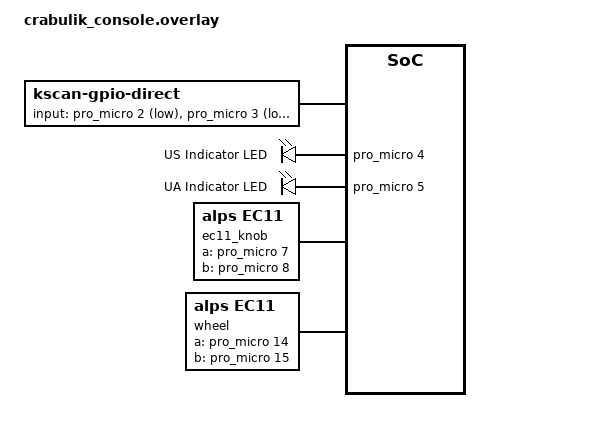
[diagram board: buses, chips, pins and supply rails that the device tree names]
#include <dt-bindings/zmk/matrix_transform.h>

/ {
    chosen {
        zmk,kscan = &kscan0;
    };

    /* Define the three physical switches wired to Ground */
    kscan0: kscan {
        compatible = "zmk,kscan-gpio-direct";
        label = "KSCAN";
        input-gpios
            = <&pro_micro 2 (GPIO_ACTIVE_LOW | GPIO_PULL_UP)> /* Button 1: US Layout */
            , <&pro_micro 3 (GPIO_ACTIVE_LOW | GPIO_PULL_UP)> /* Button 2: UA Layout */
            , <&pro_micro 6 (GPIO_ACTIVE_LOW | GPIO_PULL_UP)> /* Button 3: host-switch layer (hold) */
            , <&pro_micro 9 (GPIO_ACTIVE_LOW | GPIO_PULL_UP)> /* Button 4: EC11 push-click */
            , <&pro_micro 18 (GPIO_ACTIVE_LOW | GPIO_PULL_UP)> /* Button 5: Prev track (P1.15) */
            , <&pro_micro 19 (GPIO_ACTIVE_LOW | GPIO_PULL_UP)>; /* Button 6: Next track (P0.02) */
    };

    /* Expose the LEDs to the OS for custom state mapping */
    leds {
        compatible = "gpio-leds";
        led_us: led_us {
            gpios = <&pro_micro 4 GPIO_ACTIVE_HIGH>;
            label = "US Indicator LED";
        };
        led_ua: led_ua {
            gpios = <&pro_micro 5 GPIO_ACTIVE_HIGH>;
            label = "UA Indicator LED";
        };
    };

    /* Rotary inputs (optional add-on hardware). Both are incremental quadrature
     * encoders driven by ZMK's EC11 sensor driver. Each encoder's common (C)
     * pin goes to GND. The EC11's push-click is a separate momentary switch
     * wired into kscan0 above as Button 4 (far leg -> GND).
     *
     * Pins avoid D10/D16 (P0.09/P0.10) on purpose: those are the nRF52840 NFC
     * pins and need extra config to act as plain GPIO. D7/D8/D9/D14/D15 don't. */
    ec11_knob: encoder_ec11 {
        compatible = "alps,ec11";
        a-gpios = <&pro_micro 7 (GPIO_ACTIVE_HIGH | GPIO_PULL_UP)>;  /* P0.11 */
        b-gpios = <&pro_micro 8 (GPIO_ACTIVE_HIGH | GPIO_PULL_UP)>;  /* P1.04 */
        steps = <80>;   /* EC11 ~4 pulses/detent; tune so 1 detent = 1 tick */
        status = "okay";
    };

    wheel: encoder_wheel {
        compatible = "alps,ec11";
        a-gpios = <&pro_micro 14 (GPIO_ACTIVE_HIGH | GPIO_PULL_UP)>; /* P1.11 */
        b-gpios = <&pro_micro 15 (GPIO_ACTIVE_HIGH | GPIO_PULL_UP)>; /* P1.13 */
        steps = <24>;   /* mouse wheel ~1 pulse/detent; tune empirically */
        status = "okay";
    };

    sensors: sensors {
        compatible = "zmk,keymap-sensors";
        sensors = <&ec11_knob &wheel>;   /* order = sensor-bindings order */
        triggers-per-rotation = <20>;
    };
};
